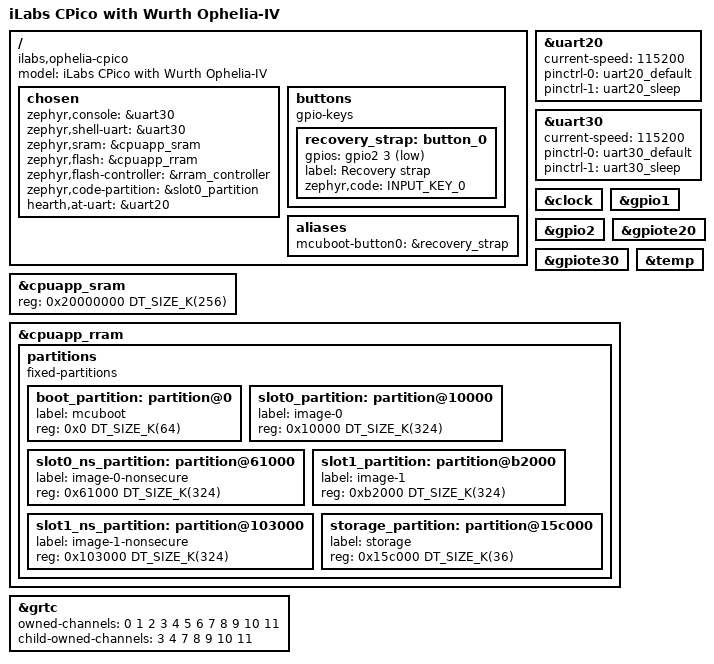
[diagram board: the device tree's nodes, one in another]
/dts-v1/;
#include <nordic/nrf54l15_cpuapp.dtsi>
#include "ophelia_cpico-pinctrl.dtsi"

/ {
    model = "iLabs CPico with Wurth Ophelia-IV";
    compatible = "ilabs,ophelia-cpico";

    chosen {
        zephyr,console = &uart30;
        zephyr,shell-uart = &uart30;
        zephyr,sram = &cpuapp_sram;
        zephyr,flash = &cpuapp_rram;
        zephyr,flash-controller = &rram_controller;
        zephyr,code-partition = &slot0_partition;
        hearth,at-uart = &uart20;
    };

    buttons {
        compatible = "gpio-keys";
        recovery_strap: button_0 {
            gpios = <&gpio2 3 (GPIO_PULL_UP | GPIO_ACTIVE_LOW)>;
            label = "Recovery strap";
            zephyr,code = <INPUT_KEY_0>;
        };
    };

    aliases {
        mcuboot-button0 = &recovery_strap;
    };
};

/* The SoC dtsi reserves 68 KB of the 256 KB physical SRAM for the
 * cpuflpr (VPR) coprocessor (nordic/nrf54l15.dtsi: cpuapp_sram defaults
 * to 188 KB). This board never runs anything on cpuflpr (no VPR
 * firmware anywhere in this repo), so reclaim the full 256 KB for
 * cpuapp; matches the pattern in every Nordic nrf54l15dk board overlay
 * ("restore full RRAM and SRAM space"). Real CHIP server bring-up
 * (Task 2, PrepareServer/StartServer with BT+OpenThread actually
 * running) overflows the default 188 KB RAM region by ~15.3 KB; the
 * Task 1 skeleton never hit this because it never started the stack.
 */
&cpuapp_sram {
    reg = <0x20000000 DT_SIZE_K(256)>;
    ranges = <0x0 0x20000000 DT_SIZE_K(256)>;
    status = "okay";
};

&uart20 {
    status = "okay";
    current-speed = <115200>;
    pinctrl-0 = <&uart20_default>;
    pinctrl-1 = <&uart20_sleep>;
    pinctrl-names = "default", "sleep";
};

&uart30 {
    status = "okay";
    current-speed = <115200>;
    pinctrl-0 = <&uart30_default>;
    pinctrl-1 = <&uart30_sleep>;
    pinctrl-names = "default", "sleep";
};

/* The legacy nrf clock driver (CLOCK_CONTROL_NRF) needs this node; it
 * is what makes the K32SRC Kconfig choice visible, and the board
 * defconfig selects the internal RC there (no 32 kHz crystal on the
 * module). */
&clock { status = "okay"; };

&gpio1 { status = "okay"; };
&gpio2 { status = "okay"; };
&gpiote20 { status = "okay"; };
&gpiote30 { status = "okay"; };

/* NRF_802154_SL (the 802.15.4 driver OpenThread/CHIP pull in) selects
 * TEMP_NRF5_MPSL for radio temperature compensation, which needs this
 * node enabled; disabled by default at the SoC dtsi level. Matches the
 * nrf54l15dk reference board. */
&temp { status = "okay"; };

&cpuapp_rram {
    partitions {
        compatible = "fixed-partitions";
        #address-cells = <1>;
        #size-cells = <1>;
        /* This fixed-partitions node is inert under sysbuild's Partition
         * Manager: pm_static.yml is the byte truth (48 KB mcuboot, 1342 KB
         * app). Kept only so bare non-sysbuild builds still link. */
        boot_partition: partition@0 {
            label = "mcuboot";
            reg = <0x0 DT_SIZE_K(64)>;
        };
        slot0_partition: partition@10000 {
            label = "image-0";
            reg = <0x10000 DT_SIZE_K(324)>;
        };
        slot0_ns_partition: partition@61000 {
            label = "image-0-nonsecure";
            reg = <0x61000 DT_SIZE_K(324)>;
        };
        slot1_partition: partition@b2000 {
            label = "image-1";
            reg = <0xb2000 DT_SIZE_K(324)>;
        };
        slot1_ns_partition: partition@103000 {
            label = "image-1-nonsecure";
            reg = <0x103000 DT_SIZE_K(324)>;
        };
        /* 32k from 0x154000 to 0x15bfff reserved for TF-M partitions */
        storage_partition: partition@15c000 {
            label = "storage";
            reg = <0x15c000 DT_SIZE_K(36)>;
        };
    };
};

/* The kernel timer. Without this the build silently falls back to a
 * SysTick configuration whose ISR never reaches the vector table, and
 * the first tick is a fatal spurious exception (found the hard way on
 * first boot). Channel split copied from the nrf54l15dk. */
&grtc {
    owned-channels = <0 1 2 3 4 5 6 7 8 9 10 11>;
    child-owned-channels = <3 4 7 8 9 10 11>;
    status = "okay";
};
